AUTOSAR XML (schema 00049)
package /Application/DltConfig
  dlt log channel to process mapping DltLogChannelToProcessMapping_SOA_DMS_TO_SOA_DMS: dlt-log-channel=SOA_DMS, process=SOA_DMS
package /Application/Executable
  executable SOA_DMS: category=APPLICATION_LEVEL, logging-behavior=USES-LOGGING, reporting-behavior=REPORTS-EXECUTION-STATE, version=1.0.0
    root sw component prototype AA: application-type=SOA_DMS
package /Application/Manifest
  service instance to port prototype mapping SOA_DMS_AA_PPort_SOA_DMS: port-prototype=AA.PPort_SOA_DMS, process=SOA_DMS, service-instance=Provider_SoaDms
  service instance to port prototype mapping SOA_DMS_AA_RPort_Zone5Dms: port-prototype=AA.RPort_Zone5Dms, process=SOA_DMS, service-instance=Consumer_Zone5Dms
package /Application/Process
  process SOA_DMS: executable=SOA_DMS, state-dependent-startup-config{function-group-state=[SC.On, SC.Verify], resource-group=DefaultResourceGroup, startup-config=SOA}
    process state machine SOA_DMS: type=ProcessState
package /Application/SwComponent
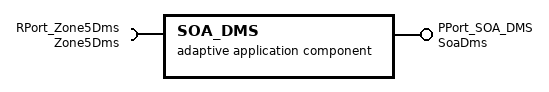
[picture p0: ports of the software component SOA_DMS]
  adaptive application sw component type SOA_DMS
    provide port PPort_SOA_DMS: provided-interface=SoaDms
    require port RPort_Zone5Dms: required-interface=Zone5Dms
